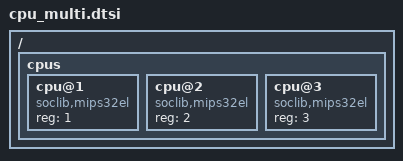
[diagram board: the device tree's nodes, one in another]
/*
 * Defines 3 slave processors in addition to the monocpu
 */

/include/ "cpu_mono.dtsi"

/ {
	cpus {
		cpu@1 {
			device_type = "cpu";
			compatible = "soclib,mips32el";
			reg = <1>;
		};
		cpu@2 {
			device_type = "cpu";
			compatible = "soclib,mips32el";
			reg = <2>;
		};
		cpu@3 {
			device_type = "cpu";
			compatible = "soclib,mips32el";
			reg = <3>;
		};
	};
};

